# USB0_VBP2APB_WRAP_CONTROLLER_VBP_CORE_ADDR_MAP register map
Vendor: Texas Instruments
Registers are 32-bit, access per field, reset 0x0 unless marked. A register's access mark holds for its fields unless they carry their own. Offsets are as the file gives them; [hi:lo] are bit positions; {n}, {i} and the like mark numbered series; 'fields as' and 'values as' point back to an identical list.

## USB0_VBP2APB_WRAP_CONTROLLER_VBP_CORE_ADDR_MAP (part 2 of 9)
0x00 VBP2APB_WRAP__CONTROLLER_VBP__CORE_ADDR_MAP_CDNS_DID ro reset 0x4024E — Cadence Device ID Register ASF parity-protected: no
  [31:0] DID — Cadence Device ID Register IP4024E
0x04 VBP2APB_WRAP__CONTROLLER_VBP__CORE_ADDR_MAP_CDNS_RID ro reset 0x200 — Cadence Revision ID Register ASF parity-protected: no
  [15:0] CDNS_RID
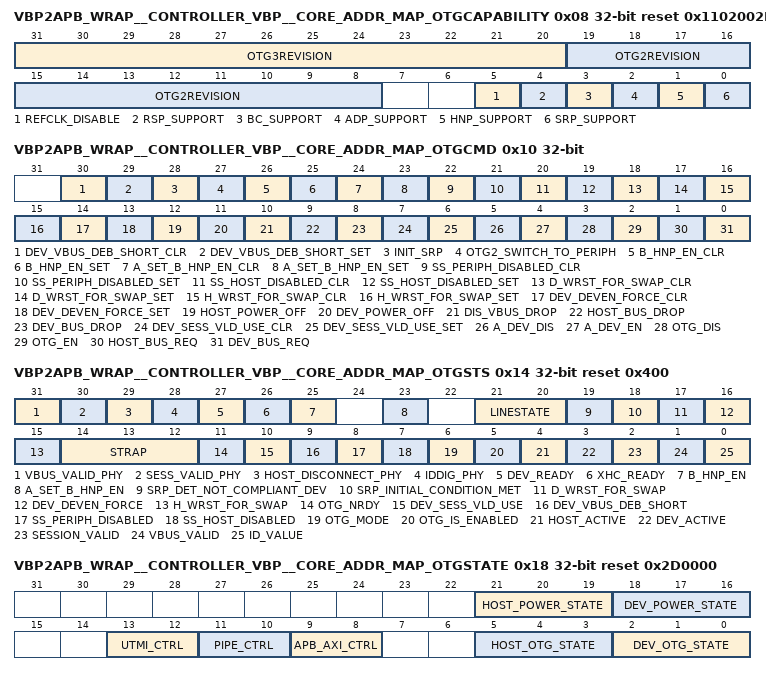
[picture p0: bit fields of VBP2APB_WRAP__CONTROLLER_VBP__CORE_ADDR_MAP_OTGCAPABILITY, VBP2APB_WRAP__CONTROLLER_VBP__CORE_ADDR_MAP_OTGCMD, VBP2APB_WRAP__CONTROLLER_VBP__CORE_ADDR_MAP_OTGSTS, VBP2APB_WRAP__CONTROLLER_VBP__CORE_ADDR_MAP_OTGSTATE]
0x08 VBP2APB_WRAP__CONTROLLER_VBP__CORE_ADDR_MAP_OTGCAPABILITY ro reset 0x1102002B — OTG Capabilities register
  [31:20] OTG3REVISION — Specifies implemeted OTG3.0 specification revision
  [19:8] OTG2REVISION — Specifies implemeted OTG2.0 specification revision
  [5] REFCLK_DISABLE — PHY Reference clock control disable. 0 - PHY Reference clock control supported 1 - PHY Reference clock control not supported
  [4] RSP_SUPPORT — RSP support. 0 - RSP not supported 1 - RSP supported
  [3] BC_SUPPORT — BC Support [Battery Charging specification rev 1.2]. 0 - BC not supported 1 - BC supported
  [2] ADP_SUPPORT — ADP support. 0 - ADP not supported 1 - ADP supported
  [1] HNP_SUPPORT — HNP support. 0 - HNP not supported 1 - HNP supported
  [0] SRP_SUPPORT — SRP support. 0 - SRP not supported 1 - SRP supported
0x10 VBP2APB_WRAP__CONTROLLER_VBP__CORE_ADDR_MAP_OTGCMD — OTGCMD
  [30] DEV_VBUS_DEB_SHORT_CLR wo — Disable forcing Device short VBUS debounce time. Setting this bit causes DEV_VBUS_DEB_SHORT bit in OTGSTS clear.
  [29] DEV_VBUS_DEB_SHORT_SET wo — Enable forcing Device short VBUS debounce time. This bit should be set while switching from Host to Device mode takes place. Setting this bit should be done in the same time when Device mode is activated [DEV_BUS_REQ]. Setting this bit causes DEV_VBUS_DEB_SHORT bit in OTGSTS set.
  [28] INIT_SRP wo — Initiate SRP
  [27] OTG2_SWITCH_TO_PERIPH wo — Switch to Peripheral mode when operating at USB 2.0
  [26] B_HNP_EN_CLR wo — This bit should be written if software wants to clear b_hnp_enable
  [25] B_HNP_EN_SET wo — This bit should be written if SetFeature[b_hnp_enable] has been accepted.
  [24] A_SET_B_HNP_EN_CLR wo — This bit should be written if upcoming USB 2.0 bus suspend should not cause Role Swap.
  [23] A_SET_B_HNP_EN_SET wo — This bit should be written if SetFeature[b_hnp_enable] has been sent.
  [22] SS_PERIPH_DISABLED_CLR wo — Enable SuperSpeed peripheral device functionality.
  [21] SS_PERIPH_DISABLED_SET wo — Disable SuperSpeed peripheral device functionality. Can be used only if Peripheral mode is not active.
  [20] SS_HOST_DISABLED_CLR wo — Enable SuperSpeed host functionality.
  [19] SS_HOST_DISABLED_SET wo — Disable SuperSpeed host functionality. Can be used only if Host mode is not active.
  [18] D_WRST_FOR_SWAP_CLR wo — Upcoming received Warm Reset should not be treated as Role Swapping indication. This bit should be set after Warm Reset for Role Swap is received on the Port
  [17] D_WRST_FOR_SWAP_SET wo — Upcoming Warm Reset will be received for Role Swapping. This bit should be set before Warm Reset for Role Swap is received on the Port
  [16] H_WRST_FOR_SWAP_CLR wo — Upcoming Warm Reset will not be generated for Role Swapping. This bit should be set after Warm Reset for Role Swap is generated on the Port
  [15] H_WRST_FOR_SWAP_SET wo — Upcoming Warm Reset will be generated for Role Swapping. This bit should be set before Warm Reset for Role Swap is generated on the Port
  [14] DEV_DEVEN_FORCE_CLR wo — Clear forcing Device DEVEN bit to 1. Setting this bit causes DEV_DEVEN_FORCE bit in OTGSTS clear.
  [13] DEV_DEVEN_FORCE_SET wo — Set forcing Device DEVEN bit to 1. This bit may be set while switching from Host to Device mode takes place. Setting this bit should be done in the same time when Device mode is activated [DEV_BUS_REQ]. Setting this bit causes DEV_DEVEN_FORCE bit in OTGSTS set.
  [12] HOST_POWER_OFF wo — Power Down CDNSXHCI.
  [11] DEV_POWER_OFF wo — Power Down USBSS-DEV.
  [10] DIS_VBUS_DROP wo — Do not disable vbus while bus is dropped. This bit is valid only if DEV_BUS_DROP or HOST_BUS_DROP are set.
  [9] HOST_BUS_DROP wo — Drop the bus for Host mode. This bit should be set when Host mode is no longer needed. It will clear HOST_ACTIVE bit is OTGSTS register
  [8] DEV_BUS_DROP wo — Drop the bus for Device mode. This bit should be set when Device mode is no longer needed. It will clear DEV_ACTIVE bit is OTGSTS register
  [7] DEV_SESS_VLD_USE_CLR wo — Device should use a_vbus_vld as vbus valid indication. This bit should be set in the same time when DEV_BUS_REQ
  [6] DEV_SESS_VLD_USE_SET wo — Device should use b_sess_vld as vbus valid indication. This bit should be set in the same time when DEV_BUS_REQ
  [5] A_DEV_DIS wo — Configure OTG as B-Device. It is only valid if OTG mode is enabled. This bit should be set in the same time when OTG_EN
  [4] A_DEV_EN wo — Configure OTG as A-Device. It is only valid if OTG mode is enabled. This bit should be set in the same time when OTG_EN
  [3] OTG_DIS wo — Disable OTG mode. It will clear OTG_IS_ENABLED bit is OTGSTS register
  [2] OTG_EN wo — Enable OTG mode. It will set OTG_IS_ENABLED bit is OTGSTS register
  [1] HOST_BUS_REQ wo — Request the bus for Host mode. It will set HOST_ACTIVE bit is OTGSTS register
  [0] DEV_BUS_REQ wo — Request the bus for Device mode. It will set DEV_ACTIVE bit is OTGSTS register
0x14 VBP2APB_WRAP__CONTROLLER_VBP__CORE_ADDR_MAP_OTGSTS ro reset 0x400 — OTGSTS
  [31] VBUS_VALID_PHY — PHY VBUS valid comparator status
  [30] SESS_VALID_PHY — PHY Session valid comparator status
  [29] HOST_DISCONNECT_PHY — PHY hostdisconnect status
  [28] IDDIG_PHY — PHY UTMI iddig status
  [27] DEV_READY — Device mode is turned on. registers in USBSS-DEV domain are accessible through APB
  [26] XHC_READY — Host mode is turned on. registers in CDNSXHCI AUX domain are accessible through APB
  [25] B_HNP_EN — SetFeature[b_hnp_enable] has been accepted.
  [23] A_SET_B_HNP_EN — SetFeature[b_hnp_enable] has been sent and is valid.
  [21:20] LINESTATE — PHY UTMI linestate status
  [19] SRP_DET_NOT_COMPLIANT_DEV — OTG A-device detected not compilant device. If this bit is set then OTG A-device should disable SRP detection until not compilant device is disconnected [SRP_NOT_COMP_DEV_REMOVED_INT]
  [18] SRP_INITIAL_CONDITION_MET — SRP initial condition are met. OTG B-device software should issue SRP puluse onli if this bit is set.
  [17] D_WRST_FOR_SWAP — Upcoming Warm Reset will be received for Role Swapping from Peripheral to Host.
  [16] DEV_DEVEN_FORCE — Device forcing DEVEN bit is enabled.
  [15] H_WRST_FOR_SWAP — Upcoming Warm Reset will be generated for Role Swapping from Host to Peripheral.
  [14:12] STRAP — Value of the strap pins. 000 - no default configuration 010 - Controller initiall configured as Host 100 - Controller initially configured as Device other - Reserved [might be used for Type-C]
  [11] OTG_NRDY — OTG Controller not ready. Software shall not read nor write any register except OTGISTS if this bit is set.
  [10] DEV_SESS_VLD_USE — Device mode vbus valid indication: 0: a_vbus_vld is used as vbus valid 1: b_sess_vld is used as vbus valid
  [9] DEV_VBUS_DEB_SHORT — Device forcing short VBUS decounce is enabled.
  [8] SS_PERIPH_DISABLED — SuperSpeed device functionality is disabled. Port will be operating at USB 2.0 speed.
  [7] SS_HOST_DISABLED — SuperSpeed host functionality is disabled. Port will be operating at USB 2.0 speed.
  [6] OTG_MODE — OTG mode: 0 - A-Device 1 - B-Device Valid only if OTG_IS_ENABLED is 1.
  [5] OTG_IS_ENABLED — OTG functionality is enabled
  [4] HOST_ACTIVE — Device mode is active. NOTE: It is possible that Host is in inactive state [even turned off] while HOST_ACTIVE is 1.
  [3] DEV_ACTIVE — Device mode is active. NOTE: It is possible that Device is in inactive state [even turned off] while DEV_ACTIVE is 1.
  [2] SESSION_VALID — The sessionvalid status visible to the controller
  [1] VBUS_VALID — The vbusvalid status visible to the controller
  [0] ID_VALUE — Current value of the ID pin visible to the controller. It is only valid when idpullup in PORTOVERRIDE_TYPE register is set to '1'. ID_VALUE must be valid within 50ms after idpullup is set to '1'
0x18 VBP2APB_WRAP__CONTROLLER_VBP__CORE_ADDR_MAP_OTGSTATE ro reset 0x2D0000 — OTGSTATE
  [21:19] HOST_POWER_STATE — Current state of the Host power controlling FSM: 3'b000 : POWER_IDLE 3'b001 : POWER_OFF_ACK 3'b010 : POWER_OFF_MAIN_ACK 3'b011 : POWER_OFF 3'b100 : POWER_ON_REQ 3'b101 : POWER_ISO_DIS 3'b110 : POWER_ON 3'b111 : POWER_ON_READY
  [18:16] DEV_POWER_STATE — Current state of the Device power controlling FSM: 3'b000 : POWER_IDLE 3'b001 : POWER_OFF_ACK 3'b010 : POWER_OFF_MAIN_ACK 3'b011 : POWER_OFF 3'b100 : POWER_ON_REQ 3'b101 : POWER_ISO_DIS 3'b110 : POWER_ON 3'b111 : POWER_ON_READY
  [13:12] UTMI_CTRL — Current state of the USB2 UTMI mux selector. 2'b00 : Both modes off. OTG takes control over UTMI [SRP,BC] 2'b01 : Host active. 2'b10 : Device active. 2'b11 : Illegal [both modes off]
  [11:10] PIPE_CTRL — Current state of the USB3 PIPE mux selector. 2'b00 : Both modes off. 2'b01 : Host active. 2'b10 : Device active. 2'b11 : Illegal [both modes off]
  [9:8] APB_AXI_CTRL — Current state of the ABP/AXI mux selector. 2'b00 : Both modes off. 2'b01 : Host active. 2'b10 : Device active. 2'b11 : Illegal [both modes off]
  [5:3] HOST_OTG_STATE — Current state of the OTG Host FSM. 3'b000 : H_IDLE 3'b001 : H_VBUS_ON 3'b010 : H_VBUS_FAILED 3'b011 : H_OTG_HOST_MODE 3'b100 : H_HOST_MODE 3'b101 : H_SWITCH_TO_DEVICE 3'b110 : H_A_SUSPEND 3'b111 : H_WAIT_VBUS_FALL
  [2:0] DEV_OTG_STATE — Current state of the OTG Device FSM. 3'b000 : DEV_IDLE 3'b001 : DEV_MODE 3'b010 : DEV_SRP 3'b011 : DEV_WAIT_VBUS_FALL 3'b100 : DEV_SWITCH_TO_HOST 3'b101 : DEV_WAIT_FOR_CONN
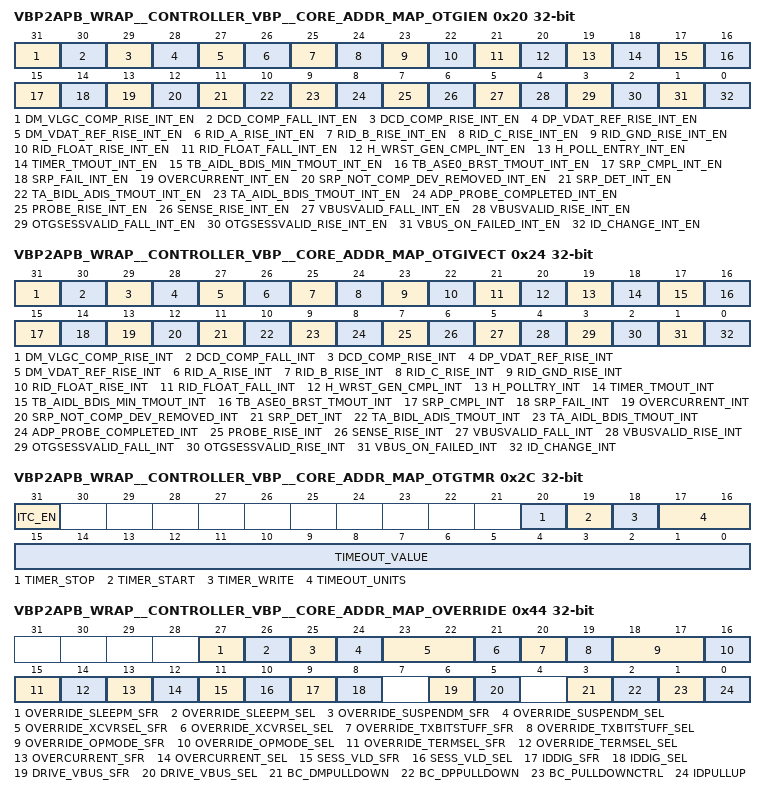
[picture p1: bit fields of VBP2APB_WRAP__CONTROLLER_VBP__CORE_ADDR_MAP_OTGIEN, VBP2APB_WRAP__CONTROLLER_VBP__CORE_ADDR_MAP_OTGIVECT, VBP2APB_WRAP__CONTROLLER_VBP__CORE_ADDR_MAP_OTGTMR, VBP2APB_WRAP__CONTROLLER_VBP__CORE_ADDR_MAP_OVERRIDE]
0x20 VBP2APB_WRAP__CONTROLLER_VBP__CORE_ADDR_MAP_OTGIEN rw — OTGIEN
  [31] DM_VLGC_COMP_RISE_INT_EN — DM VLGC comparator rise detect interrupt enable
  [30] DCD_COMP_FALL_INT_EN — DCD comparator fall detect interrupt enable
  [29] DCD_COMP_RISE_INT_EN — DCD comparator rise detect interrupt enable
  [28] DP_VDAT_REF_RISE_INT_EN — DP VDAT comparator rise detect interrupt enable
  [27] DM_VDAT_REF_RISE_INT_EN — DM VDAT comparator rise detect interrupt enable
  [26] RID_A_RISE_INT_EN — RID A comparator rise detect interrupt enable
  [25] RID_B_RISE_INT_EN — RID B comparator rise detect interrupt enable
  [24] RID_C_RISE_INT_EN — RID C comparator rise detect interrupt enable
  [23] RID_GND_RISE_INT_EN — RID GND comparator rise detect interrupt enable
  [22] RID_FLOAT_RISE_INT_EN — RID floating comparator rise detect interrupt enable
  [21] RID_FLOAT_FALL_INT_EN — RID floating comparator detect interrupt enable
  [20] H_WRST_GEN_CMPL_INT_EN — Host Warm Reset generation completed interrupt enable.
  [19] H_POLL_ENTRY_INT_EN — Host Polling state entry interrupt enable.
  [18] TIMER_TMOUT_INT_EN — Timer timeout interrupt enable.
  [17] TB_AIDL_BDIS_MIN_TMOUT_INT_EN — The bus has been in Idle state for the required time during HNP interrupt enable.
  [16] TB_ASE0_BRST_TMOUT_INT_EN — No response from A-Device to HNP interrupt enable.
  [15] SRP_CMPL_INT_EN — SRP completed interrupt enable.
  [14] SRP_FAIL_INT_EN — No response from SRP from A-Device interrupt enable.
  [13] OVERCURRENT_INT_EN — Overcurrent condition detected interrupt enable.
  [12] SRP_NOT_COMP_DEV_REMOVED_INT_EN — Non cmpliant device disconnect interrupt enable
  [11] SRP_DET_INT_EN — SRP pulse detected interrupt enable. NOTE: SRP detection can be enabled only if core is enabled to work as a A-device [OTGSTS.OTG_MODE=0]
  [10] TA_BIDL_ADIS_TMOUT_INT_EN — No activity from B-Device timeout interrupt enable.
  [9] TA_AIDL_BDIS_TMOUT_INT_EN — No response from B-Device for HNP interrupt enable.
  [8] ADP_PROBE_COMPLETED_INT_EN — ADP probe completed interrupt enable
  [7] PROBE_RISE_INT_EN — ADP probe comparator rise detected interrupt enable
  [6] SENSE_RISE_INT_EN — ADP sense comparator rise detected interrupt enable
  [5] VBUSVALID_FALL_INT_EN — Vbusvalid fall detected interrupt enable.
  [4] VBUSVALID_RISE_INT_EN — Vbusvalid fall detected interrupt enable.
  [3] OTGSESSVALID_FALL_INT_EN — Otgsessvalid fall detected interrupt enable.
  [2] OTGSESSVALID_RISE_INT_EN — Otgsessvalid rise detected interrupt enable.
  [1] VBUS_ON_FAILED_INT_EN — Enabling Vbus by A-Device has failed interrupt enable.
  [0] ID_CHANGE_INT_EN — ID change interrupt enable
0x24 VBP2APB_WRAP__CONTROLLER_VBP__CORE_ADDR_MAP_OTGIVECT access not given — OTGIVECT
  [31] DM_VLGC_COMP_RISE_INT — DM VLGC comparator rise detect interrupt (access R/W1TC)
  [30] DCD_COMP_FALL_INT — DCD comparator fall detect interrupt (access R/W1TC)
  [29] DCD_COMP_RISE_INT — DCD comparator rise detect interrupt (access R/W1TC)
  [28] DP_VDAT_REF_RISE_INT — DP VDAT comparator rise detect interrupt (access R/W1TC)
  [27] DM_VDAT_REF_RISE_INT — DM VDAT comparator rise detect interrupt (access R/W1TC)
  [26] RID_A_RISE_INT — RID A comparator rise detect interrupt (access R/W1TC)
  [25] RID_B_RISE_INT — RID B comparator rise detect interrupt (access R/W1TC)
  [24] RID_C_RISE_INT — RID C comparator rise detect interrupt (access R/W1TC)
  [23] RID_GND_RISE_INT — RID GND comparator rise detect interrupt (access R/W1TC)
  [22] RID_FLOAT_RISE_INT — RID floating comparator rise detect interrupt (access R/W1TC)
  [21] RID_FLOAT_FALL_INT — RID floating comparator detect interrupt (access R/W1TC)
  [20] H_WRST_GEN_CMPL_INT — Host Warm Reset generation completed interrupt. (access R/W1TC)
  [19] H_POLLTRY_INT — Host Polling state entry interrupt. (access R/W1TC)
  [18] TIMER_TMOUT_INT — Timer timeout interrupt. (access R/W1TC)
  [17] TB_AIDL_BDIS_MIN_TMOUT_INT — The bus has been in Idle state for the required time during HNP interrupt. (access R/W1TC)
  [16] TB_ASE0_BRST_TMOUT_INT — No response from A-Device to HNP interrupt. (access R/W1TC)
  [15] SRP_CMPL_INT — SRP completed interrupt. (access R/W1TC)
  [14] SRP_FAIL_INT — No response from SRP from A-Device interrupt. (access R/W1TC)
  [13] OVERCURRENT_INT — Overcurrent condition detected interrupt. (access R/W1TC)
  [12] SRP_NOT_COMP_DEV_REMOVED_INT — Not cmpliant device disconnect detect interrupt. (access R/W1TC)
  [11] SRP_DET_INT — SRP pulse detected interrupt. (access R/W1TC)
  [10] TA_BIDL_ADIS_TMOUT_INT — No activity from B-Device timeout interrupt. (access R/W1TC)
  [9] TA_AIDL_BDIS_TMOUT_INT — No response from B-Device for HNP interrupt. (access R/W1TC)
  [8] ADP_PROBE_COMPLETED_INT — ADP completed. Status is reported in OTGADPSTS register. (access R/W1TC)
  [7] PROBE_RISE_INT — ADP probe comparator rise detected interrupt (access R/W1TC)
  [6] SENSE_RISE_INT — ADP sense comparator rise detected interrupt (access R/W1TC)
  [5] VBUSVALID_FALL_INT — Vbusvalid fall detected interrupt. (access R/W1TC)
  [4] VBUSVALID_RISE_INT — Vbusvalid fall detected interrupt. (access R/W1TC)
  [3] OTGSESSVALID_FALL_INT — Otgsessvalid fall detected interrupt. (access R/W1TC)
  [2] OTGSESSVALID_RISE_INT — Otgsessvalid rise detected interrupt. (access R/W1TC)
  [1] VBUS_ON_FAILED_INT — Enabling Vbus by A-Device has failed. This bit should be cleared before enabling subsequent connection as host. (access R/W1TC)
  [0] ID_CHANGE_INT — ID change interrupt (access R/W1TC)
0x28 VBP2APB_WRAP__CONTROLLER_VBP__CORE_ADDR_MAP_CLK_FREQ reset 0x200000 — CLK_FREQ
  [31:16] CLK_FREQ_KHZ rw — CLK_FREQ_KHZ defines how many cycles are needed to determine 1 ms clock base for stb_clk_predft. Example: Let's say that stb_clk_predft frequency is 32kHz. With CLK_FREQ_KHZ set to 32 time base would be 32 cycles of 32khz clock which gives 1 ms
0x2C VBP2APB_WRAP__CONTROLLER_VBP__CORE_ADDR_MAP_OTGTMR — OTGTMR
  [31] ITC_EN wo — ITC ENABLE for device mode 0 - Device IOC and ISP interrupts moderation by OTG_IVECT interrupt from OTGTMR is disabled. 1 - The OTGTMR is used for Device IOC and ISP interrupts moderation. The OTG_IVECT from OTGTMR is not requested.
  [20] TIMER_STOP wo — Stop timer
  [19] TIMER_START wo — Start timer
  [18] TIMER_WRITE wo — Timer value and units write strobe
  [17:16] TIMEOUT_UNITS wo — Time units: 0 - hundreds of microseconds [valid only if otg controller clock is in MHz range] 1 - milliseconds 2 - tens of milliseconds 3 - hundreds of milliseconds Valid only if TIMER_WRITE is 1.
  [15:0] TIMEOUT_VALUE wo — Timeout value for timer. Valid only if TIMER_WRITE is 1.
0x40 VBP2APB_WRAP__CONTROLLER_VBP__CORE_ADDR_MAP_OTGSIMULATE — OTGSIMULATE
  [0] OTG_CFG_FAST_SIMS rw — Debug Feature. This bit is for simulation modes only. It enables reductions to OTG timings. '0': Normal timings '1': Enable fast simulation timing modes This bit should be written '0' in normal operation
0x44 VBP2APB_WRAP__CONTROLLER_VBP__CORE_ADDR_MAP_OVERRIDE — PORT_OVERRIDE register can be written when UTMI clock is disabled, ASF parity-protected: no
  [27] OVERRIDE_SLEEPM_SFR rw — SFR sleepm control. Value this bit is passed to PHY sleepm signal. This bit is valid only with PORT_OVERRIDE. override_sleepm_sel set to '1'.
  [26] OVERRIDE_SLEEPM_SEL rw — sleepm override select. This register allows SW driver override sleepm pin as follows: 0: sleepm is controlled from active controller [host/device/none] 1: sleepm controlled from SFR
  [25] OVERRIDE_SUSPENDM_SFR rw — SFR suspendm control. Value this bit is passed to PHY suspendm signal. This bit is valid only with PORT_OVERRIDE. override_suspendm_sel set to '1'.
  [24] OVERRIDE_SUSPENDM_SEL rw — suspendm override select. This register allows SW driver override suspendm pin as follows: 0: suspendm is controlled from active controller [host/device/none] 1: suspendm controlled from SFR
  [23:22] OVERRIDE_XCVRSEL_SFR rw — SFR xcvrselect control. Value of these bits is passed to PHY xcvrselect signal. This bit is valid only with PORT_OVERRRIDE. override_opmode_sel set to 1
  [21] OVERRIDE_XCVRSEL_SEL rw — xcvrselect override select. This register allows SW driver override xcvrselect pin as follows: 0: xcvrselect is controlled from active controller [host/device] 1: xcvrselect controlled from SFR
  [20] OVERRIDE_TXBITSTUFF_SFR rw — SFR txbitstuffenable control. Value this bit is passed to PHY txbitstuffenable signal. This bit is valid only with PORT_OVERRRIDE. override_txbitstuff_sel set to 1.
  [19] OVERRIDE_TXBITSTUFF_SEL rw — txbitstuffenable override select. This register allows SW driver override txbitstuffenable pin as follows: 0: txbitstuffenable is controlled from active controller [host/device] 1: txbitstuffenable controlled from SFR
  [18:17] OVERRIDE_OPMODE_SFR rw — SFR opmode control. Value these bits is passed to PHY opmode signal. This bit is valid only with PORT_OVERRRIDE. override_opmode_sel set to 1.
  [16] OVERRIDE_OPMODE_SEL rw — opmode override select. This register allows SW driver override opmode pin as follows: 0: opmode is controlled from active controller [host/device] 1: opmode controlled from SFR
  [15] OVERRIDE_TERMSEL_SFR rw — SFR overcurrent control. 0: overcurrent = 0 1: overcurrent = 1 This bit is valid only with PORT_OVERRRIDE.overcurrent_sel set to '1'. Note: overcurrent active state is low.
  [14] OVERRIDE_TERMSEL_SEL rw — termselect override select. This register allows SW driver override termselect pin as follows: 0: txbitstuffenable is controlled from active controller [host/device] 1: txbitstuffenable controlled from SFR
  [13] OVERCURRENT_SFR rw — SFR termselect control. Value this bit is passed to PHY termselect signal. This bit is valid only with PORT_OVERRRIDE. override_termsel_sel set to 1.
  [12] OVERCURRENT_SEL rw — Overcurrent override select This register allows SW driver override overcurrent pin as follows: 0: overcurrent is controlled from external FAULT detector 1: overcurrent controlled from SFR
  [11] SESS_VLD_SFR rw — SFR Vbusvalid/Sessvalid control. 0: Vbusvalid/Sessvalid = 0 1: Vbusvalid/Sessvalid = 1 This bit is valid only with PORT_OVERRRIDE.sess_vld_sel set to '1'.
  [10] SESS_VLD_SEL rw — Vbusvalid/Sessvalid override select. This register allows SW driver override Vbusvalid/Sessvalid pins as follows: 0: Vbusvalid/Sessvalid are controlled from OTG PHY 1: Vbusvalid/Sessvalid are controlled from SFR
  [9] IDDIG_SFR rw — SFR iddig control. 0: iddig = 0 1: iddig = 1 This bit is valid only with PORT_OVERRRIDE.iddig_sel set to '1'.
  [8] IDDIG_SEL rw — IDDIG override select. This register allows SW driver override iddig pin as follows: 0: iddig is controlled from OTG PHY 1: iddig controlled from SFR
  [6] DRIVE_VBUS_SFR rw — 0: drive_vbus = 0 1: drive_vbus = 1 This bit is valid only with USB2_PORT_OVERRRIDE.drive_vbus_sel set to '1'. This bit is auto-cleared upon over-current condition. Over-current doesn't disable vbus forcing.
  [5] DRIVE_VBUS_SEL rw — This register allows SW driver take control over drive_vbus as follows: 0: drive_vbus controlled from OTG controller 1: drive_vbus controlled from SFR
  [3] BC_DMPULLDOWN rw — dmpulldown enable This bit is valid only with PORT_OVERRRIDE.pulldownctrl_sel set to 1
  [2] BC_DPPULLDOWN rw — BC dppulldown enable This bit is valid only with PORT_OVERRRIDE.pulldownctrl_sel set to 1
  [1] BC_PULLDOWNCTRL rw — pulldowncotrol 1: puldowns are controlled by dppulldown_sfr and dmpulldown_sfr 0: puldowns are controlled by OTG
  [0] IDPULLUP rw — ID Pin Sample Enable: Active High. Signal that enables the sampling of the analog ID line. 0: Sampling of ID pin is disabled, iddig is not valid 1: Sampling of ID pin is enabled
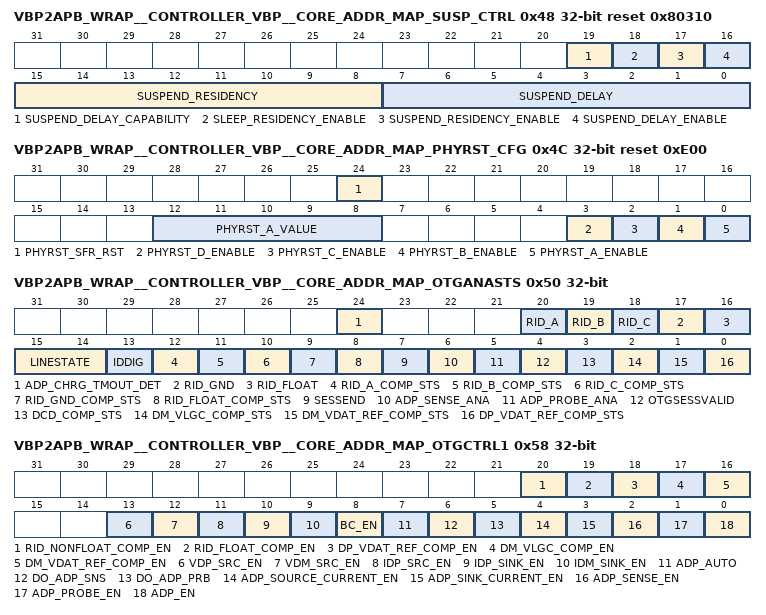
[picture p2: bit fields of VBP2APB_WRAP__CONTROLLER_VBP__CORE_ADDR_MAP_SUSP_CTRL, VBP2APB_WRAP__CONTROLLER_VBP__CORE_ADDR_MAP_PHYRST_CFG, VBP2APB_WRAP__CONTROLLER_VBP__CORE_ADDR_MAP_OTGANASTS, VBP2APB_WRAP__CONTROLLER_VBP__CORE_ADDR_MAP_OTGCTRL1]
0x48 VBP2APB_WRAP__CONTROLLER_VBP__CORE_ADDR_MAP_SUSP_CTRL reset 0x80310 — SUSP_TIMING_CTRL. This is a vendor defined capability. This register is reserved. This register should not be accessed by software. It is described only for informative purposes. This is a configuration only register, therefore it can be changed by Software only during configuration phase when Power-On Reset (pwrup_rst_n) is asserted. ASF parity-protected: no
  [19] SUSPEND_DELAY_CAPABILITY ro — Suspend delay capability. This is a configuration only field, therefore it can be changed by Software only during configuration phase when Power-On Reset [pwrup_rst_n] is asserted.
  [18] SLEEP_RESIDENCY_ENABLE rw — sleep minimum residency enable. This is a configuration only field, therefore it can be changed by Software only during configuration phase when Power-On Reset [pwrup_rst_n] is asserted.
  [17] SUSPEND_RESIDENCY_ENABLE rw — suspend minimum residency enable. This is a configuration only field, therefore it can be changed by Software only during configuration phase when Power-On Reset [pwrup_rst_n] is asserted.
  [16] SUSPEND_DELAY_ENABLE rw — suspend delay enable. This is a configuration only field, therefore it can be changed by Software only during configuration phase when Power-On Reset [pwrup_rst_n] is asserted.
  [15:8] SUSPEND_RESIDENCY rw — Suspend/Sleep minimum residency time [us]. This is a configuration only field, therefore it can be changed by Software only during configuration phase when Power-On Reset [pwrup_rst_n] is asserted.
  [7:0] SUSPEND_DELAY rw — Suspend assertion delay time [us]. This is a configuration only field, therefore it can be changed by Software only during configuration phase when Power-On Reset [pwrup_rst_n] is asserted.
0x4C VBP2APB_WRAP__CONTROLLER_VBP__CORE_ADDR_MAP_PHYRST_CFG reset 0xE00 — USB20 PHY reset workaround config ASF parity-protected: no
  [24] PHYRST_SFR_RST rw — Software USB20 PHy reset: 0 - SW utmi_reset not asserted 1 - SW utmi_reset asserted
  [12:8] PHYRST_A_VALUE rw — phyrst_a Rx fail timeout value. Value of this register is used as a timeout value for detecting Rx fail [utmi_rxactive is not up during Rx] Value of this register represent maximum number of UTMI clock cycles where utmi_rxactive is expected to rise with respect to Rx start judged by non-idle state utmi_linestate
  [3] PHYRST_D_ENABLE rw — Reset PHY after each utmi_opmode change from 2'b10 to any other value: 0 - disabled 1 - enabled
  [2] PHYRST_C_ENABLE rw — Reset PHY after each utmi_opmode change from 2'b01 to any other value: 0 - disabled 1 - enabled
  [1] PHYRST_B_ENABLE rw — Reset PHY after each transmitted packet in High-Speed: 0 - disabled 1 - enabled
  [0] PHYRST_A_ENABLE rw — Reset PHY if Rx fail is detected: 0 - disabled 1 - enabled
0x50 VBP2APB_WRAP__CONTROLLER_VBP__CORE_ADDR_MAP_OTGANASTS ro — OTGADPBCSTS
  [24] ADP_CHRG_TMOUT_DET — ADP charge timeout detected
  [20] RID_A — RID A status reg
  [19] RID_B — RID B status reg
  [18] RID_C — RID C status reg
  [17] RID_GND — RID GND status reg
  [16] RID_FLOAT — RID float status reg
  [15:14] LINESTATE — Line State: These signals reflect the current state of the single ended receivers. They are combinatorial until a 'usable' sieclock is available, then they are synchronized to sieclock. They reflect the current state of the DP [linestate [0]] and DM [linestate [1]] signals. 00: SE0 [Single Ended Zero] 01: 'J' State 10: 'K' State 11: SE1 [Single Ended One]
  [13] IDDIG — ID Pin Status: Indicates whether the connected USB plug is Micro-A or Micro-B. This is only valid when idpullup is set to '1'. It must be valid within 50ms after idpullup is set to '1'. 0: Connected plug is a Micro-A 1: Connected plug is a Micro-B
  [12] RID_A_COMP_STS — RID A comparator status 1: RID_A Detected on ID Pin 0: RID_A not Detected on ID Pin
  [11] RID_B_COMP_STS — RID B comparator status 1: RID_B Detected on ID Pin 0: RID_B not Detected on ID Pin
  [10] RID_C_COMP_STS — RID C comparator status 1: RID_C Detected on ID Pin 0: RID_C not Detected on ID Pin
  [9] RID_GND_COMP_STS — RID GND comparator status 1: RID_GND Detected on ID Pin 0: RID_GND not Detected on ID Pin
  [8] RID_FLOAT_COMP_STS — RID float comparator status 1: RID_FLOAT Detected on ID Pin 0: RID_FLOAT not Detected on ID Pin
  [7] SESSEND — VBUS Valid: Indicates if the voltage on VBUS is at a valid level for operation [4.4V less than VTH less than 4.75V]. 0: VBUS less than 4.4V 1: VBUS > 4.75V
  [6] ADP_SENSE_ANA — Output of ADP Sense Comparator. 0: VBUS less than 0.2V 1: VBUS > 0.55V
  [5] ADP_PROBE_ANA — Output of ADP Probe Comparator. 0: VBUS less than 0.6V 1: VBUS > 0.75V
  [4] OTGSESSVALID — B-Peripheral is Valid: Indicates if the session for a B-Peripheral is valid [0.8V less than VTH less than 4.0V]. The signal bvalid from OTG 1.3 is now renamed as otgsessvalid. 0: VBUS less than 0.8V 1: VBUS > 4.0V
  [3] DCD_COMP_STS — Data Contact Detect [DCD] Comparator Status 1: DP line is asserted 0: DP line is not asserted
  [2] DM_VLGC_COMP_STS — 1: DM > VLGC Detected 0: DM less than VLGC Detected Note: This status shall be re-used from the single ended receiver output of D- whenever dm_vlgc_comp_en is '1'.
  [1] DM_VDAT_REF_COMP_STS — 1: DM > VDAT_REF Detected 0: DM less than VDAT_REF Detected Note: This status shall be re-used from the single ended receiver output of D- whenever dm_vdat_ref_comp_en is '1'.
  [0] DP_VDAT_REF_COMP_STS — 1: DP > VDAT_REF Detected 0: DP less than VDAT_REF Detected Note: This status shall be re-used from the single ended receiver output of D+ whenever dp_vdat_ref_comp_en is '1'.
0x54 VBP2APB_WRAP__CONTROLLER_VBP__CORE_ADDR_MAP_ADP_RAMP_TIME ro — ADP_RAMP_TIME
  [31:0] ADP_RAMP_TIME — ADP ramp time measurement value. Software should read this register upon ADP_PROBE_COMPLETED_INT_EN interrupt detection
0x58 VBP2APB_WRAP__CONTROLLER_VBP__CORE_ADDR_MAP_OTGCTRL1 — OTGCTRL1
  [20] RID_NONFLOAT_COMP_EN rw — 1: RID Non-Float Comparator Enabled 0: RID Non-Float Comparator Disabled Note: This ID Comparator enable is used to detect the presence of RID_A or RID_B or RID_C or RID_GND when the ID pin is non-floating.
  [19] RID_FLOAT_COMP_EN rw — 1: RID Float Comparator Enabled 0: RID Float Comparator Disabled Note: This ID Comparator enable is used to detect whether the ID line is floating or non-floating. If it is identified to be non-floating, then rid_nonfloat_comp_en is enabled to check for RID_A or RID_B or RID_C or RID_GND.
  [18] DP_VDAT_REF_COMP_EN rw — 1: DP to VDAT_REF Comparator Enabled 0: DP to VDAT_REF Comparator Disabled
  [17] DM_VLGC_COMP_EN rw — 1: DM to VLGC Comparator Enabled 0: DM to VLGC Comparator Disabled
  [16] DM_VDAT_REF_COMP_EN rw — 1: DM to VDAT_REF Comparator Enabled 0: DM to VDAT_REF Comparator Disabled
  [13] VDP_SRC_EN rw — 1: Voltage Source on DP Enabled 0: Voltage Source on DP Disabled
  [12] VDM_SRC_EN rw — 1: Voltage Source on DM Enabled 0: Voltage Source on DM Disabled
  [11] IDP_SRC_EN rw — 1: Current Source on DP Enabled 0: Current Source on DP Disabled
  [10] IDP_SINK_EN rw — 1: Current Sink on DP Enabled 0: Current Sink on DP Disabled
  [9] IDM_SINK_EN rw — 1: Current Sink on DM Enabled 0: Current Sink on DM Disabled
  [8] BC_EN rw — Battery Charging Circuits Master Enable. 1: BC Enabled 0: BC Disabled
  [7] ADP_AUTO rw — ADP mode. If set to 1 ADP probing is controlled by internal FSM. If set to 0 then software should control ADP sequence.
  [6] DO_ADP_SNS rw — ADP sensing enable in automated mode
  [5] DO_ADP_PRB rw — ADP probing enable in automated mode
  [4] ADP_SOURCE_CURRENT_EN rw — When this signal is high, VBUS is charged to the probe threshold [0.75V]. This signal should be asserted 5us after the assertion of adp_en. 0: ADP Source Current Enable OFF 1: ADP Source Current Enable ON
  [3] ADP_SINK_CURRENT_EN rw — When this signal is high, VBUS is discharged to ground. This signal should be asserted 5us after the assertion of adp_en. 0: ADP Sink Current Enable OFF 1: ADP Sink Current Enable ON
  [2] ADP_SENSE_EN rw — This signal enables the probe mode of the ADP. During this mode, sense comparators and the current sources will be ON based on the source and sink current enables. 0: ADP Probe Sense OFF 1: ADP Probe Sense ON
  [1] ADP_PROBE_EN rw — This signal enables the probe mode of the ADP. During this mode, probe comparators and the current sources will be ON based on the source and sink current enables. 0: ADP Probe Mode OFF 1: ADP Probe Mode ON
  [0] ADP_EN rw — ADP Feature Enable. This signal is the master enable for all the ADP PHY logics. 0: ADP Logics are powered OFF 1: ADP Logics are powered ON
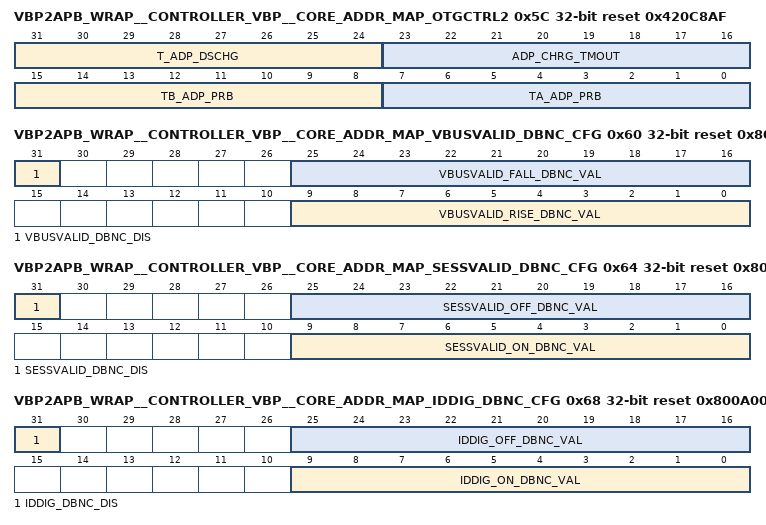
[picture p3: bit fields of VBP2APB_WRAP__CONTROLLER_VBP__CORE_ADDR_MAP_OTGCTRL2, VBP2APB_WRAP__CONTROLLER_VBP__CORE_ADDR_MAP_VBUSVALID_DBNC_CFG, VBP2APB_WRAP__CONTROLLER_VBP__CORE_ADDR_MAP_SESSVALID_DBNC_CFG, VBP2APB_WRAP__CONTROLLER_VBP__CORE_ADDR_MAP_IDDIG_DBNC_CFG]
0x5C VBP2APB_WRAP__CONTROLLER_VBP__CORE_ADDR_MAP_OTGCTRL2 rw reset 0x420C8AF — OTGCTRL2
  [31:24] T_ADP_DSCHG — ADP probing discharge time. T_ADP_DSCHG = {reg_value} * 1 ms
  [23:16] ADP_CHRG_TMOUT — ADP probing timeout value. Defines maximum time for ADP charging. If this time is reached during charging then adp_chrg_tmout_det bit in OTGADPBCSTS is set ADP_CHRG_TMOUT = {reg_value} * 1 ms
  [15:8] TB_ADP_PRB — B-device ADP probing period. TB_ADP_PRB = {reg_value} * 10 ms
  [7:0] TA_ADP_PRB — A-device ADP probing period. TA_ADP_PRB = {reg_value} * 10 ms
0x60 VBP2APB_WRAP__CONTROLLER_VBP__CORE_ADDR_MAP_VBUSVALID_DBNC_CFG reset 0x800A000A — VBUSVALID_DBNC_CFG ASF parity-protected: no
  [31] VBUSVALID_DBNC_DIS rw — Vbusvalid debounce disable
  [25:16] VBUSVALID_FALL_DBNC_VAL rw — Vbusvalid off debounce: Debounce timer value = reg value x 100us
  [9:0] VBUSVALID_RISE_DBNC_VAL rw — Vbusvalid on debounce: Debounce timer value = reg value x 100us
0x64 VBP2APB_WRAP__CONTROLLER_VBP__CORE_ADDR_MAP_SESSVALID_DBNC_CFG reset 0x800A0100 — SESSVALID_DBNC_CFG ASF parity-protected: no
  [31] SESSVALID_DBNC_DIS rw — Sessvalid debounce disable
  [25:16] SESSVALID_OFF_DBNC_VAL rw — Sessvalid off debounce: Debounce timer value = reg value x 100us
  [9:0] SESSVALID_ON_DBNC_VAL rw — Sessvalid on debounce: Debounce timer value = reg value x 100us
0x68 VBP2APB_WRAP__CONTROLLER_VBP__CORE_ADDR_MAP_IDDIG_DBNC_CFG reset 0x800A000A — IDDIG_DBNC_CFG ASF parity-protected: no
  [31] IDDIG_DBNC_DIS rw — Iddig debounce disable
  [25:16] IDDIG_OFF_DBNC_VAL rw — Sessvalid off debounce: Debounce timer value = reg value x 100us
  [9:0] IDDIG_ON_DBNC_VAL rw — Sessvalid on debounce: Debounce timer value = reg value x 100us
0x8C VBP2APB_WRAP__CONTROLLER_VBP__CORE_ADDR_MAP_DB_ASF_MEM_MASK rw reset 0xFFFFFFFF — Cadence Device ID Register ASF parity-protected: no
  [31:0] DB_ASF_MEM_MASK — Debug Feature. 0-DISABLE/1-ENABLE ECC check for memories
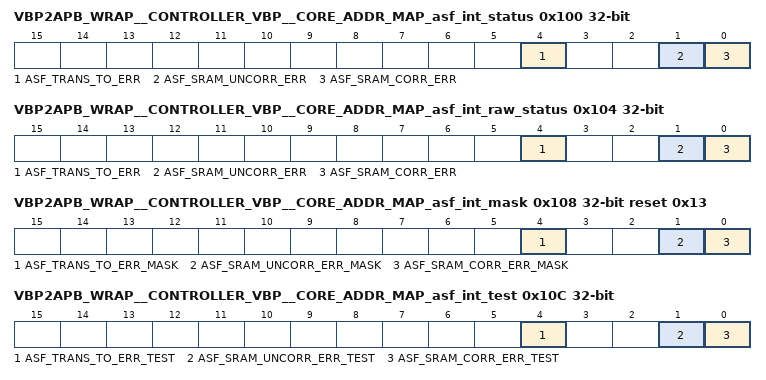
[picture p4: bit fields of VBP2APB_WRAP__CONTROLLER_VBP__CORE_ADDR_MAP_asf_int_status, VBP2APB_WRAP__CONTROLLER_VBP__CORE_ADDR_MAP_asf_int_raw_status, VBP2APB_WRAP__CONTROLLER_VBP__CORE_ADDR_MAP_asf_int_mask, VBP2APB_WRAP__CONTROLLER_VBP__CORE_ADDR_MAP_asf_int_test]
0x100 VBP2APB_WRAP__CONTROLLER_VBP__CORE_ADDR_MAP_asf_int_status access not given — ASF Interrupt Status Register. This register indicates the source of ASF interrupts. The corresponding bit in the mask register must be clear for a bit to be set. If any bit is set in this register the asf_fatal or asf_nonfatal signal will be asserted. Writing to either raw or masked status registers, clear both registers. For test purposes, trigger signal interrupt event by writing to the ASF interrupt status test register. ASF parity-protected: no
  [4] ASF_TRANS_TO_ERR — Transaction timeouts error interrupt (access R/W1TC)
  [1] ASF_SRAM_UNCORR_ERR — SRAM uncorrectable error interrupt (access R/W1TC)
  [0] ASF_SRAM_CORR_ERR — SRAM correctable error interrupt (access R/W1TC)
0x104 VBP2APB_WRAP__CONTROLLER_VBP__CORE_ADDR_MAP_asf_int_raw_status access not given — ASF Interrupt Raw Status Register. A bit set in this raw register indicates a source of ASF fault in the correspoding feature. Writing to either raw or masked status registers, clear both registers. For test purposes, trigger signal interrupt event by writing to the ASF interrrupt status test register. ASF parity-protected: no
  fields as VBP2APB_WRAP__CONTROLLER_VBP__CORE_ADDR_MAP_asf_int_status
0x108 VBP2APB_WRAP__CONTROLLER_VBP__CORE_ADDR_MAP_asf_int_mask reset 0x13 — The ASF interrupt mask register indicating which interrupt bits in the ASF interrupt status register are masked. All bits are set at reset. Clear the individual bit to enable the corresponding interrupt. ASF parity-protected: yes (only byte 0 protected)
  [4] ASF_TRANS_TO_ERR_MASK rw — Mask bit for transaction timeouts error interrupt.
  [1] ASF_SRAM_UNCORR_ERR_MASK rw — Mask bit for SRAM uncorrectable error interrupt.
  [0] ASF_SRAM_CORR_ERR_MASK rw — Mask bit for SRAM correctable error interrupt.
0x10C VBP2APB_WRAP__CONTROLLER_VBP__CORE_ADDR_MAP_asf_int_test — The ASF interrupt test register emulate hardware even. Write one to individual bit to trigger single event in (masked and raw) status registers according to mask and will generate interrrupt accordingly. ASF parity-protected: no
  [4] ASF_TRANS_TO_ERR_TEST wo — Test bit for transaction timeouts error interrupt.
  [1] ASF_SRAM_UNCORR_ERR_TEST wo — Test bit for SRAM uncorrectable error interrupt.
  [0] ASF_SRAM_CORR_ERR_TEST wo — Test bit for SRAM correctable error interrupt.
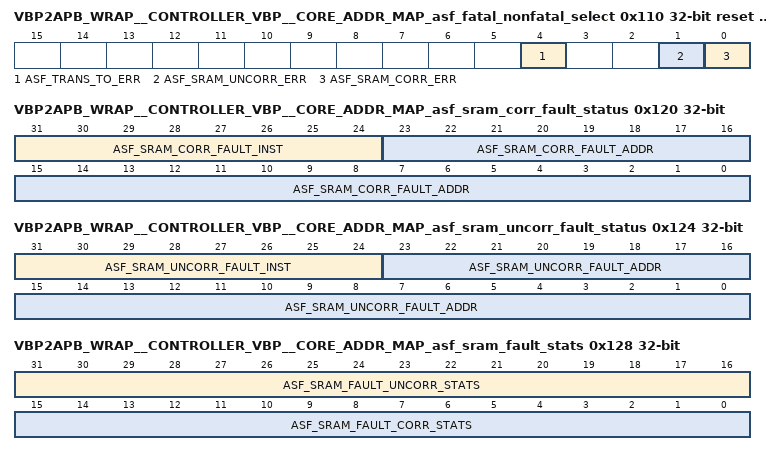
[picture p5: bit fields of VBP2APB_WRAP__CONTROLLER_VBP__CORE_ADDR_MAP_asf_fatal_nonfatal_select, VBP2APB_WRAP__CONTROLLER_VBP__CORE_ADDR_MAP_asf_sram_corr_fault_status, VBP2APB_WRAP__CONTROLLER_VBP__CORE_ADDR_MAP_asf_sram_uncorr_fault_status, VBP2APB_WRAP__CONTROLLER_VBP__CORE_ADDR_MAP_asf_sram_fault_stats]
0x110 VBP2APB_WRAP__CONTROLLER_VBP__CORE_ADDR_MAP_asf_fatal_nonfatal_select reset 0x13 — The fatal or non-fatal interrupt register selects whether a fatal (asf_int_fatal) or non-fatal (asf_int_nonfatal) interrupt is triggered. If the bit of the event will be set to one then fatal interrupt (asf_int_fatal) will be triggered. Otherwise the non-fatal interrupt (asf_int_nonfatal) will be triggered. ASF parity-protected: yes (only byte 0 protected)
  [4] ASF_TRANS_TO_ERR rw — Enable transaction timeouts error interrupt as fatal.
  [1] ASF_SRAM_UNCORR_ERR rw — Enable SRAM uncorrectable error interrupt as fatal.
  [0] ASF_SRAM_CORR_ERR rw — Enable SRAM correctable error interrupt as fatal.
{0xFC+4i} VBP2APB_WRAP__CONTROLLER_VBP__CORE_ADDR_MAP_RSVD_{i}_ASF ro (i=6..8) — Reserved: Reserved for future RO implementations. Registers or memory that shall be treated as read-only by system software. Rsvd registers shall return zero when read. Software shall ignore the value read from these bits.
0x120 VBP2APB_WRAP__CONTROLLER_VBP__CORE_ADDR_MAP_asf_sram_corr_fault_status ro — Status register for SRAM correctable fault. These fields are updated whenever asf_sram_corr_fault input is active. ASF parity-protected: no
  [31:24] ASF_SRAM_CORR_FAULT_INST — Last SRAM instance that generated fault.
  [23:0] ASF_SRAM_CORR_FAULT_ADDR — Last SRAM address that generated fault.
0x124 VBP2APB_WRAP__CONTROLLER_VBP__CORE_ADDR_MAP_asf_sram_uncorr_fault_status ro — Status register for SRAM uncorrectable fault. These fields are updated whenever asf_sram_uncorr_fault input is active. ASF parity-protected: no
  [31:24] ASF_SRAM_UNCORR_FAULT_INST — Last SRAM instance that generated fault.
  [23:0] ASF_SRAM_UNCORR_FAULT_ADDR — Last SRAM address that generated fault.
0x128 VBP2APB_WRAP__CONTROLLER_VBP__CORE_ADDR_MAP_asf_sram_fault_stats access not given — Statistics register for SRAM faults. Note that this register clears when software writes to any field. ASF parity-protected: no
  [31:16] ASF_SRAM_FAULT_UNCORR_STATS — Count of number of uncorrectable errors if implemented. Count value will saturate at 0xffff. (access R/W1TC)
  [15:0] ASF_SRAM_FAULT_CORR_STATS — Count of number of correctable errors if implemented. Count value will saturate at 0xffff. (access R/W1TC)
0x12C VBP2APB_WRAP__CONTROLLER_VBP__CORE_ADDR_MAP_RSVD_12_ASF ro — Reserved: Reserved for future RO implementations. Registers or memory that shall be treated as read-only by system software. Rsvd registers shall return zero when read. Software shall ignore the value read from these bits.
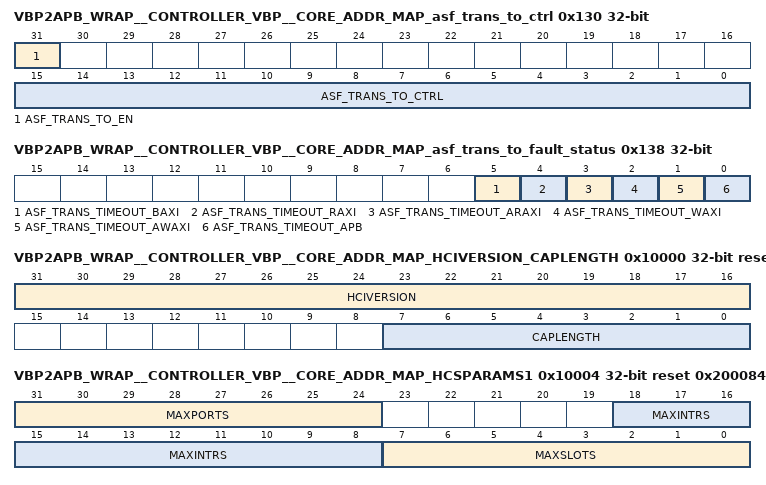
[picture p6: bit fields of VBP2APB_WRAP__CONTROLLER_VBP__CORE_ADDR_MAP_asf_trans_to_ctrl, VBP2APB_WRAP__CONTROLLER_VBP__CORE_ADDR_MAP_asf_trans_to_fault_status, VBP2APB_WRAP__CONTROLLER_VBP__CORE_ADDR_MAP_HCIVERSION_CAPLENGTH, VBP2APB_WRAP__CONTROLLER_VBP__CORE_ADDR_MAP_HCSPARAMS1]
0x130 VBP2APB_WRAP__CONTROLLER_VBP__CORE_ADDR_MAP_asf_trans_to_ctrl — Control register to configure the ASF transaction timeout monitors. ASF parity-protected: yes (only bytes 0, 1 and 3 protected. Byte 2 is not protected)
  [31] ASF_TRANS_TO_EN rw — Enable transaction timeout monitoring.
  [15:0] ASF_TRANS_TO_CTRL rw — Timer value to use for transaction timeout monitor.
0x134 VBP2APB_WRAP__CONTROLLER_VBP__CORE_ADDR_MAP_asf_trans_to_fault_mask rw reset 0xFFFFFFFF — Control register to mask out ASF transaction timeout faults from triggering interrupts. On reset, all bits are set to mask out all sources. Clear the corresponding bit to enable the interrupt source. The width of this field is parametrisable and the bit definitions are implementation specific. ASF parity-protected: yes
  [31:0] ASF_TRANS_TO_FAULT_MASK — Mask register for each ASF transaction timeout fault source.
0x138 VBP2APB_WRAP__CONTROLLER_VBP__CORE_ADDR_MAP_asf_trans_to_fault_status access not given — Status register for transaction timeouts fault. If a fault occurs the relevant status bit will be set to 1. Each bit can be cleared by software writing 1 to each bit. ASF parity-protected: no
  [5] ASF_TRANS_TIMEOUT_BAXI — Status bits for transaction timeouts faults - AXI Timeout [BAXI] (access R/W1TC)
  [4] ASF_TRANS_TIMEOUT_RAXI — Status bits for transaction timeouts faults - AXI Timeout [RAXI] (access R/W1TC)
  [3] ASF_TRANS_TIMEOUT_ARAXI — Status bits for transaction timeouts faults - AXI Timeout [ARAXI] (access R/W1TC)
  [2] ASF_TRANS_TIMEOUT_WAXI — Status bits for transaction timeouts faults - AXI Timeout [WAXI] (access R/W1TC)
  [1] ASF_TRANS_TIMEOUT_AWAXI — Status bits for transaction timeouts faults - AXI Timeout [AWAXI] (access R/W1TC)
  [0] ASF_TRANS_TIMEOUT_APB — Status bit for transaction timeout faults - APB timeout. (access R/W1TC)
{0xFC+4i} VBP2APB_WRAP__CONTROLLER_VBP__CORE_ADDR_MAP_RSVD_{i}_ASF ro (i=16..18) — Reserved: Reserved for future RO implementations. Registers or memory that shall be treated as read-only by system software. Rsvd registers shall return zero when read. Software shall ignore the value read from these bits.
0x10000 VBP2APB_WRAP__CONTROLLER_VBP__CORE_ADDR_MAP_HCIVERSION_CAPLENGTH ro reset 0x1000080 — HCIVERSION_CAPLENGTH
  [31:16] HCIVERSION — Host Controller Interface Version Number [HCIVERSION]. This is a two-byte register containing a BCD encoding of the xHCI specification revision number supported by this host controller. The most significant byte of this register represents a major revision and the least significant byte is the minor revision. e.g. 0100h corresponds to xHCI version 1.0.
  [7:0] CAPLENGTH — Capability Registers Length [CAPLENGTH]. This register is used as an offset to add to register base to find the beginning of the Operational Register Space.
0x10004 VBP2APB_WRAP__CONTROLLER_VBP__CORE_ADDR_MAP_HCSPARAMS1 ro reset 0x2000840 — Structural Parameters 1 (HCSPARAMS1). This register defines basic structural parameters supported by this xHC implementation: Number of Device Slots support, Interrupters, Root Hub ports.
  [31:24] MAXPORTS — Number of Ports [MaxPorts]. This field specifies the maximum Port Number value, i.e. the highest numbered Port Register Set that are addressable in the Operational Register Space. Valid values are in the range of 1h to FFh. The value in this field shall reflect the maximum Port Number value assigned by an xHCI Supported Protocol Capability, described in section 7.2 of xHCI specification. Software shall refer to these capabilities to identify whether a specific Port Number is valid, and the protocol supported by the associated Port Register Set.
  [18:8] MAXINTRS — Number of Interrupters [MaxIntrs]. This field specifies the number of Interrupters implemented on this host controller. Each Interrupter may be allocated to a MSI or MSI-X vector and controls its generation and moderation. The value of this field determines how many Interrupter Register Sets are addressable in the Runtime Register Space [refer to section 5.5 of xHCI specification]. Valid values are in the range of 1h to 400h. A '0' in this field is undefined.
  [7:0] MAXSLOTS — Number of Device Slots [MaxSlots]. This field specifies the maximum number of Device Context Structures and Doorbell Array entries this host controller can support. Valid values are in the range of 1 to 255. The value of 0 is reserved.
